# MOTOR register map
Registers are 32-bit, access not given, no defined reset value unless marked. A register's access mark holds for its fields unless they carry their own. Addresses are absolute; registers are grouped by the start of their names; [hi:lo] are bit positions; {n}, {i} and the like mark numbered series.

## OUTPUTCTRL
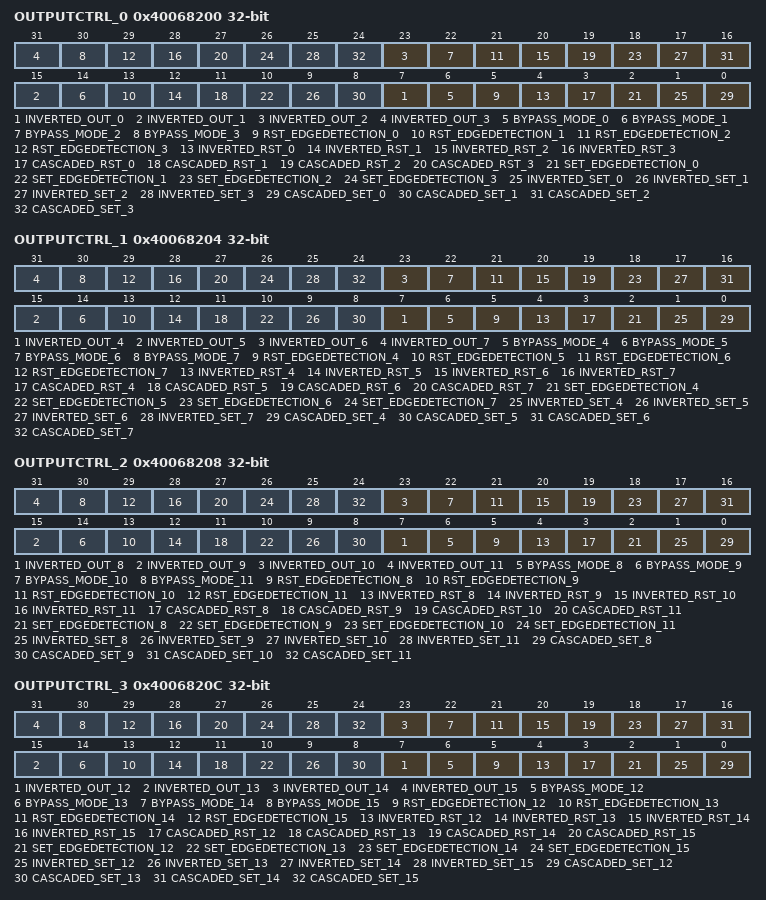
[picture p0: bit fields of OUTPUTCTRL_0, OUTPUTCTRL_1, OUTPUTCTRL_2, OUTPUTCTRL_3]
0x40068200 OUTPUTCTRL_0
  [8n+7] INVERTED_OUT_{n} (n=0..3), [8n+6] BYPASS_MODE_{n} (n=0..3), [8n+5] RST_EDGEDETECTION_{n} (n=0..3), [8n+4] INVERTED_RST_{n} (n=0..3), [8n+3] CASCADED_RST_{n} (n=0..3), [8n+2] SET_EDGEDETECTION_{n} (n=0..3), [8n+1] INVERTED_SET_{n} (n=0..3), [8n] CASCADED_SET_{n} (n=0..3)
0x40068204 OUTPUTCTRL_1
  [8n-25] INVERTED_OUT_{n} (n=4..7), [8n-26] BYPASS_MODE_{n} (n=4..7), [8n-27] RST_EDGEDETECTION_{n} (n=4..7), [8n-28] INVERTED_RST_{n} (n=4..7), [8n-29] CASCADED_RST_{n} (n=4..7), [8n-30] SET_EDGEDETECTION_{n} (n=4..7), [8n-31] INVERTED_SET_{n} (n=4..7), [8n-32] CASCADED_SET_{n} (n=4..7)
0x40068208 OUTPUTCTRL_2
  [8n-57] INVERTED_OUT_{n} (n=8..11), [8n-58] BYPASS_MODE_{n} (n=8..11), [8n-59] RST_EDGEDETECTION_{n} (n=8..11), [8n-60] INVERTED_RST_{n} (n=8..11), [8n-61] CASCADED_RST_{n} (n=8..11), [8n-62] SET_EDGEDETECTION_{n} (n=8..11), [8n-63] INVERTED_SET_{n} (n=8..11), [8n-64] CASCADED_SET_{n} (n=8..11)
0x4006820C OUTPUTCTRL_3
  [8n-89] INVERTED_OUT_{n} (n=12..15), [8n-90] BYPASS_MODE_{n} (n=12..15), [8n-91] RST_EDGEDETECTION_{n} (n=12..15), [8n-92] INVERTED_RST_{n} (n=12..15), [8n-93] CASCADED_RST_{n} (n=12..15), [8n-94] SET_EDGEDETECTION_{n} (n=12..15), [8n-95] INVERTED_SET_{n} (n=12..15), [8n-96] CASCADED_SET_{n} (n=12..15)
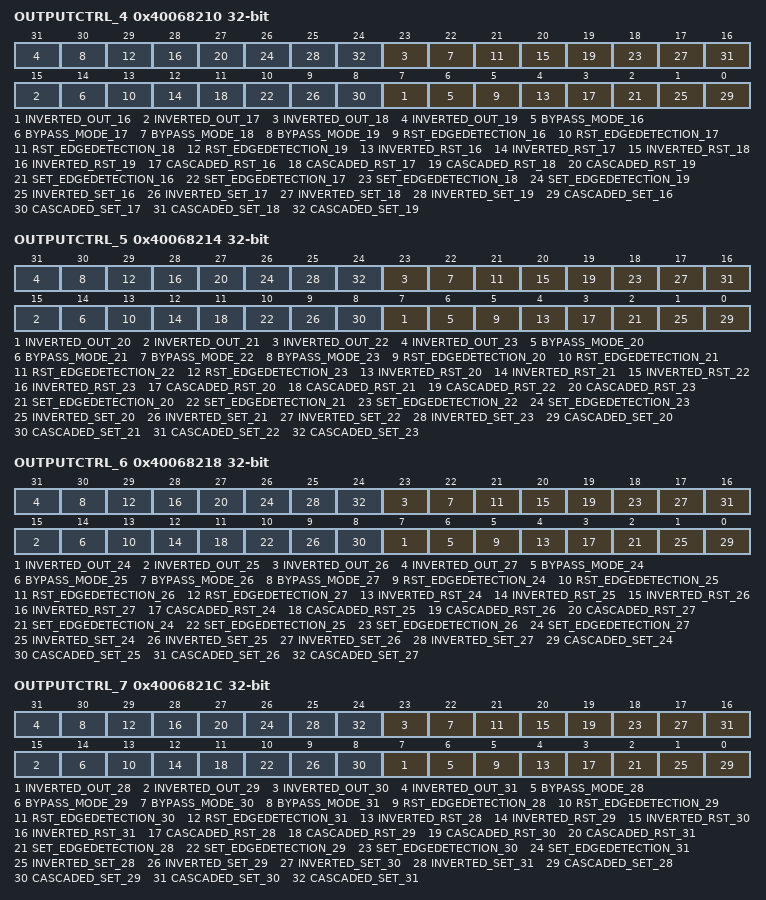
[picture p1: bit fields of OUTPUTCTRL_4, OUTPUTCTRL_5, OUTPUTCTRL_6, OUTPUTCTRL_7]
0x40068210 OUTPUTCTRL_4
  [8n-121] INVERTED_OUT_{n} (n=16..19), [8n-122] BYPASS_MODE_{n} (n=16..19), [8n-123] RST_EDGEDETECTION_{n} (n=16..19), [8n-124] INVERTED_RST_{n} (n=16..19), [8n-125] CASCADED_RST_{n} (n=16..19), [8n-126] SET_EDGEDETECTION_{n} (n=16..19), [8n-127] INVERTED_SET_{n} (n=16..19), [8n-128] CASCADED_SET_{n} (n=16..19)
0x40068214 OUTPUTCTRL_5
  [8n-153] INVERTED_OUT_{n} (n=20..23), [8n-154] BYPASS_MODE_{n} (n=20..23), [8n-155] RST_EDGEDETECTION_{n} (n=20..23), [8n-156] INVERTED_RST_{n} (n=20..23), [8n-157] CASCADED_RST_{n} (n=20..23), [8n-158] SET_EDGEDETECTION_{n} (n=20..23), [8n-159] INVERTED_SET_{n} (n=20..23), [8n-160] CASCADED_SET_{n} (n=20..23)
0x40068218 OUTPUTCTRL_6
  [8n-185] INVERTED_OUT_{n} (n=24..27), [8n-186] BYPASS_MODE_{n} (n=24..27), [8n-187] RST_EDGEDETECTION_{n} (n=24..27), [8n-188] INVERTED_RST_{n} (n=24..27), [8n-189] CASCADED_RST_{n} (n=24..27), [8n-190] SET_EDGEDETECTION_{n} (n=24..27), [8n-191] INVERTED_SET_{n} (n=24..27), [8n-192] CASCADED_SET_{n} (n=24..27)
0x4006821C OUTPUTCTRL_7
  [8n-217] INVERTED_OUT_{n} (n=28..31), [8n-218] BYPASS_MODE_{n} (n=28..31), [8n-219] RST_EDGEDETECTION_{n} (n=28..31), [8n-220] INVERTED_RST_{n} (n=28..31), [8n-221] CASCADED_RST_{n} (n=28..31), [8n-222] SET_EDGEDETECTION_{n} (n=28..31), [8n-223] INVERTED_SET_{n} (n=28..31), [8n-224] CASCADED_SET_{n} (n=28..31)
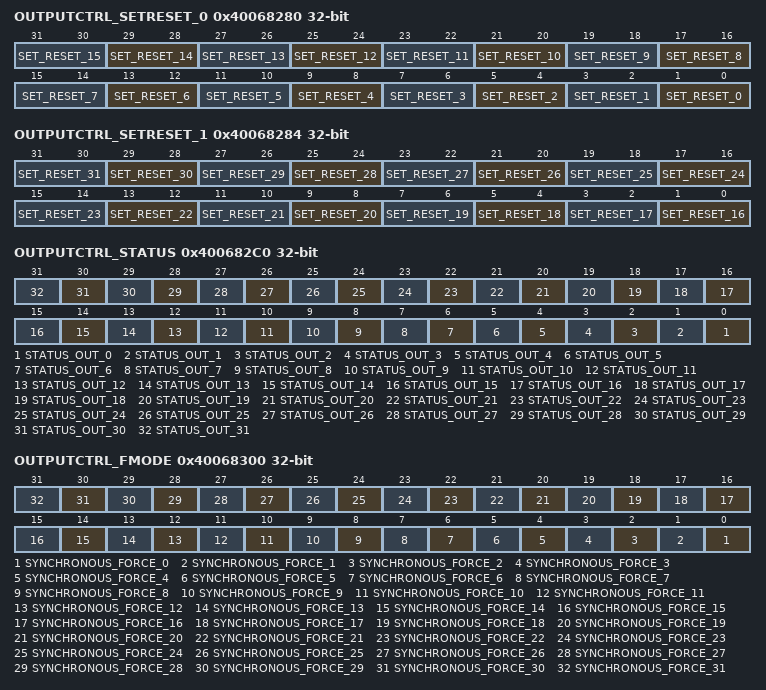
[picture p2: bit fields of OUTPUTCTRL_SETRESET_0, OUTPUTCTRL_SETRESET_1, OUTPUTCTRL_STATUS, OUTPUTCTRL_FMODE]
0x40068280 OUTPUTCTRL_SETRESET_0 wo
  [2n+1:2n] SET_RESET_{n} (n=0..15)
0x40068284 OUTPUTCTRL_SETRESET_1 wo
  [2n-31:2n-32] SET_RESET_{n} (n=16..31)
0x400682C0 OUTPUTCTRL_STATUS ro
  [n] STATUS_OUT_{n} (n=0..31)
0x40068300 OUTPUTCTRL_FMODE
  [n] SYNCHRONOUS_FORCE_{n} (n=0..31)
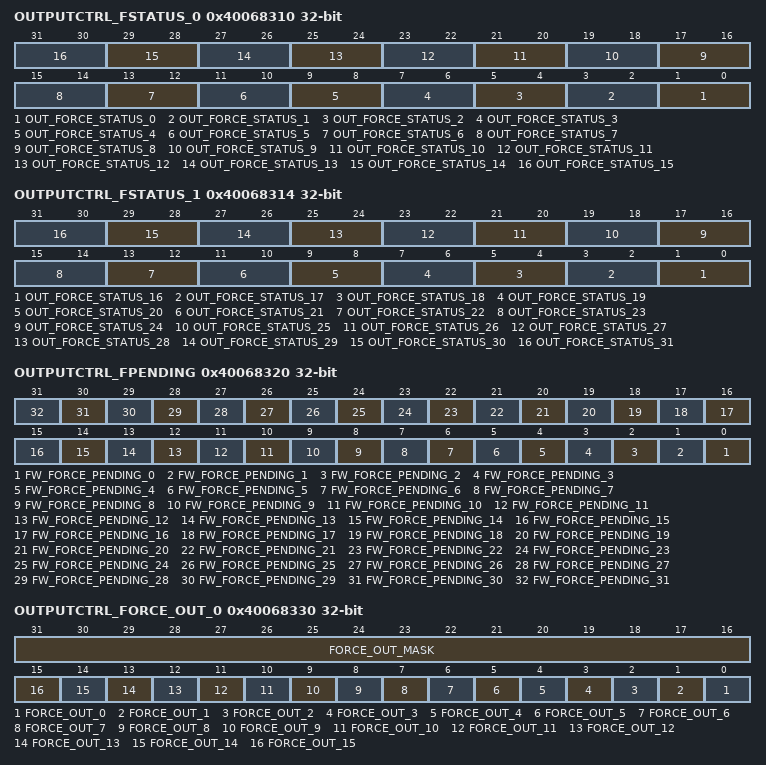
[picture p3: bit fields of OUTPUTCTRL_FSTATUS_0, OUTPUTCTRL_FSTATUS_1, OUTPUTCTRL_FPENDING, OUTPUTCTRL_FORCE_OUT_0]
0x40068310 OUTPUTCTRL_FSTATUS_0 ro
  [2n+1:2n] OUT_FORCE_STATUS_{n} (n=0..15)
0x40068314 OUTPUTCTRL_FSTATUS_1 ro
  [2n-31:2n-32] OUT_FORCE_STATUS_{n} (n=16..31)
0x40068320 OUTPUTCTRL_FPENDING
  [n] FW_FORCE_PENDING_{n} (n=0..31)
0x40068330 OUTPUTCTRL_FORCE_OUT_0 wo
  [31:16] FORCE_OUT_MASK, [n] FORCE_OUT_{n} (n=0..15)
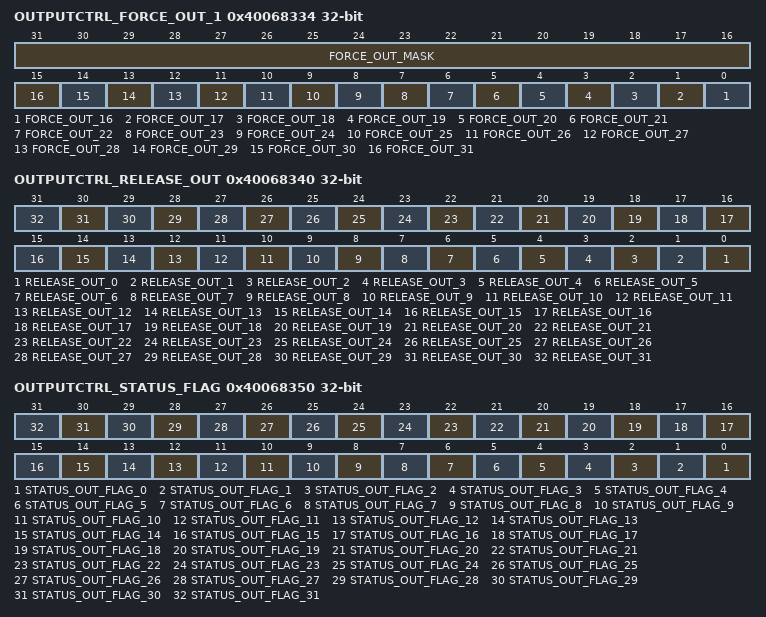
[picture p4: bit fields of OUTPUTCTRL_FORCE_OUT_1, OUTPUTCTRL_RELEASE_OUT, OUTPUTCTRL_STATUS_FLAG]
0x40068334 OUTPUTCTRL_FORCE_OUT_1 wo
  [31:16] FORCE_OUT_MASK, [n-16] FORCE_OUT_{n} (n=16..31)
0x40068340 OUTPUTCTRL_RELEASE_OUT wo
  [n] RELEASE_OUT_{n} (n=0..31)
0x40068350 OUTPUTCTRL_STATUS_FLAG
  [n] STATUS_OUT_FLAG_{n} (n=0..31)

## SFR
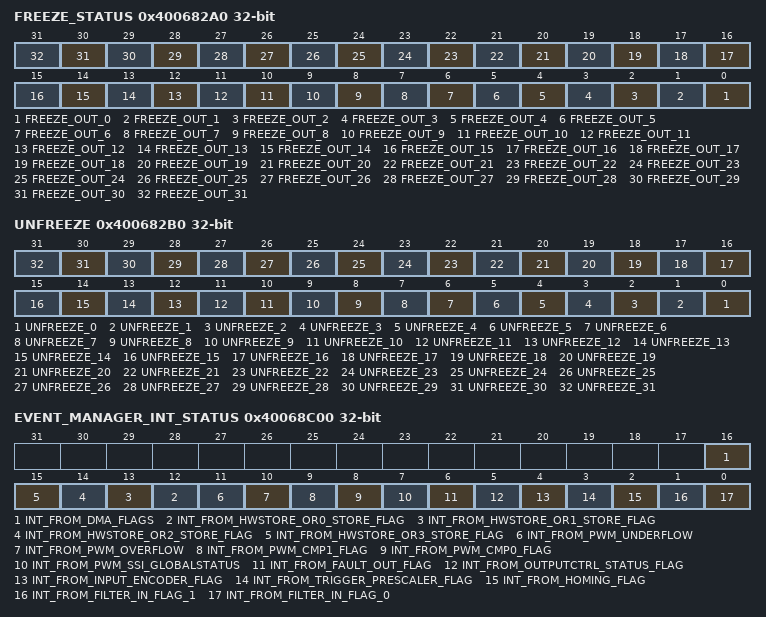
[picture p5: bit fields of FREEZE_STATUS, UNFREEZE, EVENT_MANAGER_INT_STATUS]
0x400682A0 FREEZE_STATUS
  [n] FREEZE_OUT_{n} (n=0..31)
0x400682B0 UNFREEZE wo
  [n] UNFREEZE_{n} (n=0..31)
0x40068C00 EVENT_MANAGER_INT_STATUS ro
  [16] INT_FROM_DMA_FLAGS, [n+12] INT_FROM_HWSTORE_OR{n}_STORE_FLAG (n=0..3), [11] INT_FROM_PWM_UNDERFLOW, [10] INT_FROM_PWM_OVERFLOW, [9] INT_FROM_PWM_CMP1_FLAG, [8] INT_FROM_PWM_CMP0_FLAG, [7] INT_FROM_PWM_SSI_GLOBALSTATUS, [6] INT_FROM_FAULT_OUT_FLAG, [5] INT_FROM_OUTPUTCTRL_STATUS_FLAG, [4] INT_FROM_INPUT_ENCODER_FLAG, [3] INT_FROM_TRIGGER_PRESCALER_FLAG, [2] INT_FROM_HOMING_FLAG, [1] INT_FROM_FILTER_IN_FLAG_1, [0] INT_FROM_FILTER_IN_FLAG_0
